# ESP32-S31 register map
Vendor: ESPRESSIF SYSTEMS (SHANGHAI) CO., LTD.; Series: ESP32 S-Series; File version: 1
CPU: RV32IMAFC r0p0, little endian, no MPU, FPU, 0 interrupt priority bits
Address unit: 32 bits
Registers are 32-bit, read-write, reset 0x0 unless marked. A register's access mark holds for its fields unless they carry their own. Offsets are from the block's base; [hi:lo] are bit positions; {n}, {i} and the like mark numbered series.

## LP_HUK — LP_HUK Peripheral
Base 0x20703000
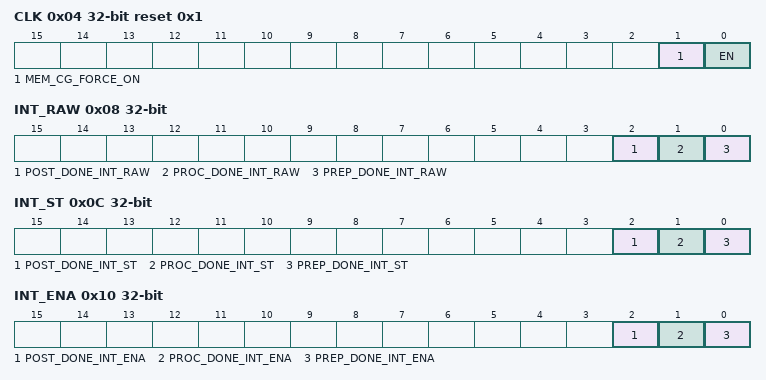
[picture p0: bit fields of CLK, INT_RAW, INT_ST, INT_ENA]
0x04 CLK reset 0x1 — HUK Generator clock gate control register
  [1] MEM_CG_FORCE_ON — Write 1 to force on memory clock gate.
  [0] EN — Write 1 to force on register clock gate.
0x08 INT_RAW ro — HUK Generator interrupt raw register, valid in level.
  [2] POST_DONE_INT_RAW — The raw interrupt status bit for the huk_post_done_int interrupt
  [1] PROC_DONE_INT_RAW — The raw interrupt status bit for the huk_proc_done_int interrupt
  [0] PREP_DONE_INT_RAW — The raw interrupt status bit for the huk_prep_done_int interrupt
0x0C INT_ST ro — HUK Generator interrupt status register.
  [2] POST_DONE_INT_ST — The masked interrupt status bit for the huk_post_done_int interrupt
  [1] PROC_DONE_INT_ST — The masked interrupt status bit for the huk_proc_done_int interrupt
  [0] PREP_DONE_INT_ST — The masked interrupt status bit for the huk_prep_done_int interrupt
0x10 INT_ENA — HUK Generator interrupt enable register.
  [2] POST_DONE_INT_ENA — The interrupt enable bit for the huk_post_done_int interrupt
  [1] PROC_DONE_INT_ENA — The interrupt enable bit for the huk_proc_done_int interrupt
  [0] PREP_DONE_INT_ENA — The interrupt enable bit for the huk_prep_done_int interrupt
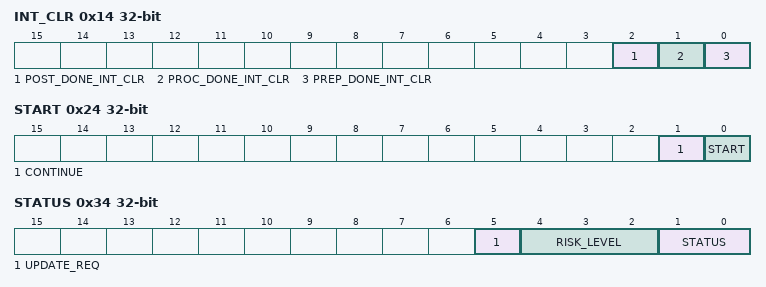
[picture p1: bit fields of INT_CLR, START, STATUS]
0x14 INT_CLR wo — HUK Generator interrupt clear register.
  [2] POST_DONE_INT_CLR — Set this bit to clear the huk_post_done_int interrupt
  [1] PROC_DONE_INT_CLR — Set this bit to clear the huk_proc_done_int interrupt
  [0] PREP_DONE_INT_CLR — Set this bit to clear the huk_prep_done_int interrupt
0x20 CONF — HUK Generator configuration register
  [0] MODE — Set this field to choose the huk process. 1: process huk generate mode. 0: process huk recovery mode.
0x24 START wo — HUK Generator control register
  [1] CONTINUE — Write 1 to start HUK Generator at IDLE state.
  [0] START — Write 1 to continue HUK Generator operation at LOAD/GAIN state.
0x28 STATE ro — HUK Generator state register
  [1:0] STATE — The state of HUK Generator. 0: IDLE. 1: LOAD. 2: GAIN. 3: BUSY.
0x34 STATUS ro — HUK Generator HUK status register
  [5] UPDATE_REQ — The update request of HUK info. 0: User can update HUK info according to the risk level. 1: The HUK info is expired, and user need to update it.
  [4:2] RISK_LEVEL — The risk level of HUK. 0-6: the higher the risk level is, the more error bits there are in the PUF SRAM. 7: Error Level, HUK is invalid.
  [1:0] STATUS — The HUK generation status. 0: HUK is not generated. 1: HUK is generated and valid. 2: HUK is generated but invalid. 3: reserved.
0xFC DATE reset 0x2404070 — Version control register
  [27:0] DATE — HUK Generator version control register.
{0x100+i} INFO_MEM[{i}] (i=0..383) 8-bit access not given — The memory that stores HUK info.

## IOMUX_MSPI_PIN — IOMUX_MSPI_PIN Peripheral
Base 0x20584000
0x00 CLK_EN0 reset 0x1 — apb registers auto clock gating reg
  [0] REG_CLK_EN — 1: auto clock gating on 0: auto clock gating off
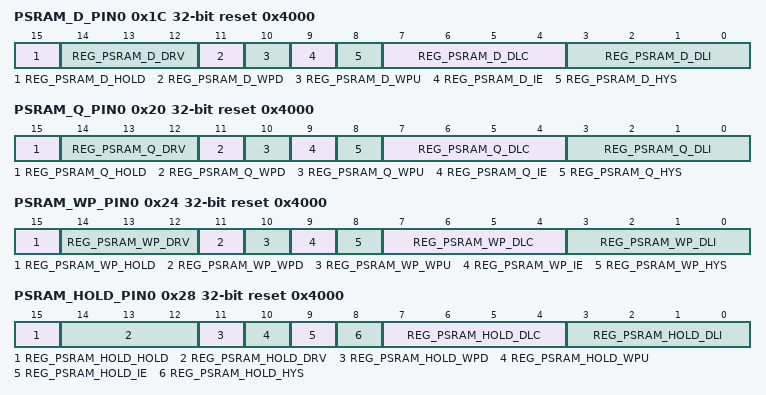
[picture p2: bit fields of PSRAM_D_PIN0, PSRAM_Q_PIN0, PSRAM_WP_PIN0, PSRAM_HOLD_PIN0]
0x1C PSRAM_D_PIN0 reset 0x4000 — IOMUX_MSPI_PIN_PSRAM_D_PIN0_REG
  [15] REG_PSRAM_D_HOLD — psram d hold
  [14:12] REG_PSRAM_D_DRV — psram d drv
  [11] REG_PSRAM_D_WPD — psram d wpd
  [10] REG_PSRAM_D_WPU — psram d wpu
  [9] REG_PSRAM_D_IE — Reserved
  [8] REG_PSRAM_D_HYS — psram d sl
  [7:4] REG_PSRAM_D_DLC — psram d dlc
  [3:0] REG_PSRAM_D_DLI — psram d dli
0x20 PSRAM_Q_PIN0 reset 0x4000 — IOMUX_MSPI_PIN_PSRAM_D_PIN0_REG
  [15] REG_PSRAM_Q_HOLD — psram q hold
  [14:12] REG_PSRAM_Q_DRV — psram q drv
  [11] REG_PSRAM_Q_WPD — psram q wpd
  [10] REG_PSRAM_Q_WPU — psram q wpu
  [9] REG_PSRAM_Q_IE — Reserved
  [8] REG_PSRAM_Q_HYS — psram q sl
  [7:4] REG_PSRAM_Q_DLC — psram q dlc
  [3:0] REG_PSRAM_Q_DLI — psram q dli
0x24 PSRAM_WP_PIN0 reset 0x4000 — IOMUX_MSPI_PIN_PSRAM_D_PIN0_REG
  [15] REG_PSRAM_WP_HOLD — psram wp hold
  [14:12] REG_PSRAM_WP_DRV — psram wp drv
  [11] REG_PSRAM_WP_WPD — psram wp wpd
  [10] REG_PSRAM_WP_WPU — psram wp wpu
  [9] REG_PSRAM_WP_IE — Reserved
  [8] REG_PSRAM_WP_HYS — psram wp sl
  [7:4] REG_PSRAM_WP_DLC — psram wp dlc
  [3:0] REG_PSRAM_WP_DLI — psram wp dli
0x28 PSRAM_HOLD_PIN0 reset 0x4000 — IOMUX_MSPI_PIN_PSRAM_D_PIN0_REG
  [15] REG_PSRAM_HOLD_HOLD — psram hold hold
  [14:12] REG_PSRAM_HOLD_DRV — psram hold drv
  [11] REG_PSRAM_HOLD_WPD — psram hold wpd
  [10] REG_PSRAM_HOLD_WPU — psram hold wpu
  [9] REG_PSRAM_HOLD_IE — Reserved
  [8] REG_PSRAM_HOLD_HYS — psram hold sl
  [7:4] REG_PSRAM_HOLD_DLC — psram hold dlc
  [3:0] REG_PSRAM_HOLD_DLI — psram hold dli
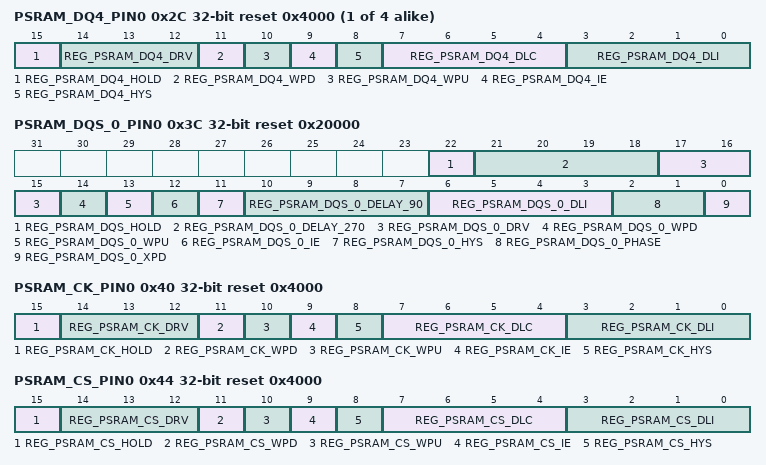
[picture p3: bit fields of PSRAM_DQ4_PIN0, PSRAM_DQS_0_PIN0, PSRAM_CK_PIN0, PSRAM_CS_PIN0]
{0x1C+4i} PSRAM_DQ{i}_PIN0 reset 0x4000 (i=4..7) — IOMUX_MSPI_PIN_PSRAM_D_PIN0_REG
  [15] REG_PSRAM_DQ{i}_HOLD — psram dq{i} hold
  [14:12] REG_PSRAM_DQ{i}_DRV — psram dq{i} drv
  [11] REG_PSRAM_DQ{i}_WPD — psram dq{i} wpd
  [10] REG_PSRAM_DQ{i}_WPU — psram dq{i} wpu
  [9] REG_PSRAM_DQ{i}_IE — Reserved
  [8] REG_PSRAM_DQ{i}_HYS — psram dq{i} sl
  [7:4] REG_PSRAM_DQ{i}_DLC — psram dq{i} dlc
  [3:0] REG_PSRAM_DQ{i}_DLI — psram dq{i} dli
0x3C PSRAM_DQS_0_PIN0 reset 0x20000 — IOMUX_MSPI_PIN_PSRAM_D_PIN0_REG
  [22] REG_PSRAM_DQS_HOLD — psram dqs hold
  [21:18] REG_PSRAM_DQS_0_DELAY_270 — psram dqs0 delay 270
  [17:15] REG_PSRAM_DQS_0_DRV — psram dqs0 drv
  [14] REG_PSRAM_DQS_0_WPD — psram dqs0 wpd
  [13] REG_PSRAM_DQS_0_WPU — psram dqs0 wpu
  [12] REG_PSRAM_DQS_0_IE — Reserved
  [11] REG_PSRAM_DQS_0_HYS — psram dqs0 sl
  [10:7] REG_PSRAM_DQS_0_DELAY_90 — psram dqs0 delay 90
  [6:3] REG_PSRAM_DQS_0_DLI — psram dqs0 dli
  [2:1] REG_PSRAM_DQS_0_PHASE — psram dqs0 phase
  [0] REG_PSRAM_DQS_0_XPD — psram xpd dqs0
0x40 PSRAM_CK_PIN0 reset 0x4000 — IOMUX_MSPI_PIN_PSRAM_D_PIN0_REG
  [15] REG_PSRAM_CK_HOLD — psram ck hold
  [14:12] REG_PSRAM_CK_DRV — psram ck drv
  [11] REG_PSRAM_CK_WPD — psram ck wpd
  [10] REG_PSRAM_CK_WPU — psram ck wpu
  [9] REG_PSRAM_CK_IE — Reserved
  [8] REG_PSRAM_CK_HYS — psram ck sl
  [7:4] REG_PSRAM_CK_DLC — psram ck dlc
  [3:0] REG_PSRAM_CK_DLI — psram ck dli
0x44 PSRAM_CS_PIN0 reset 0x4000 — IOMUX_MSPI_PIN_PSRAM_D_PIN0_REG
  [15] REG_PSRAM_CS_HOLD — psram cs hold
  [14:12] REG_PSRAM_CS_DRV — psram cs drv
  [11] REG_PSRAM_CS_WPD — psram cs wpd
  [10] REG_PSRAM_CS_WPU — psram cs wpu
  [9] REG_PSRAM_CS_IE — Reserved
  [8] REG_PSRAM_CS_HYS — psram cs sl
  [7:4] REG_PSRAM_CS_DLC — psram cs dlc
  [3:0] REG_PSRAM_CS_DLI — psram cs dli
